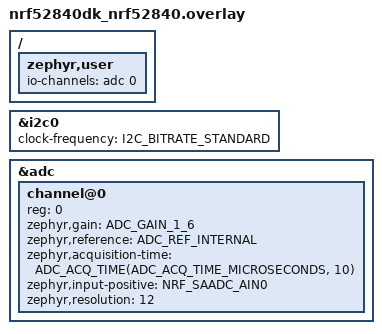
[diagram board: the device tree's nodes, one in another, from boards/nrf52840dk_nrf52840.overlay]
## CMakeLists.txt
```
#
# CMakeLists.txt -- IAQ edge node (nRF52840 DK)
#
cmake_minimum_required(VERSION 3.20.0)

find_package(Zephyr REQUIRED HINTS $ENV{ZEPHYR_BASE})
project(iaq_edge_node)

target_sources(app PRIVATE
    src/main.c
    src/sensirion_common.c
    src/scd41.c
    src/sps30.c
    src/ccs811.c
    src/mcp9808.c
    src/ldr.c
)
```

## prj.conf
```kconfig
# prj.conf -- IAQ edge node

# ---- Bluetooth: broadcaster / beacon only ----
CONFIG_BT=y
CONFIG_BT_PERIPHERAL=n
CONFIG_BT_CENTRAL=n
CONFIG_BT_BROADCASTER=y
CONFIG_BT_DEVICE_NAME="IAQ-Node"

# ---- Peripherals ----
CONFIG_I2C=y
CONFIG_ADC=y

# ---- Sensor maths needs float printf ----
CONFIG_FPU=y
CONFIG_CBPRINTF_FP_SUPPORT=y
CONFIG_NEWLIB_LIBC=y
CONFIG_NEWLIB_LIBC_FLOAT_PRINTF=y

# ---- Logging over RTT (works without a UART cable) ----
CONFIG_LOG=y
CONFIG_USE_SEGGER_RTT=y
CONFIG_LOG_BACKEND_RTT=y
CONFIG_LOG_BACKEND_UART=n

# Roomier main stack for the sensor work
CONFIG_MAIN_STACK_SIZE=4096
```

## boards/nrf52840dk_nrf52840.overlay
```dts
/*
 * nrf52840dk_nrf52840.overlay -- IAQ edge node
 *
 * I2C0 on the nRF52840 DK Arduino header defaults to:
 *     SDA = P0.26 , SCL = P0.27
 * All I2C sensors (SCD41, SPS30, CCS811, MCP9808) share this bus.
 * If you want different pins, add a &pinctrl block; otherwise these are used.
 *
 * The LDR divider midpoint goes to analog input AIN0 = P0.02.
 */

&i2c0 {
	status = "okay";
	clock-frequency = <I2C_BITRATE_STANDARD>;   /* 100 kHz -- safest */
};

/* SAADC channel 0 -> AIN0 (P0.02) for the LDR divider. */
&adc {
	status = "okay";
	#address-cells = <1>;
	#size-cells = <0>;

	channel@0 {
		reg = <0>;
		zephyr,gain = "ADC_GAIN_1_6";
		zephyr,reference = "ADC_REF_INTERNAL";
		zephyr,acquisition-time = <ADC_ACQ_TIME(ADC_ACQ_TIME_MICROSECONDS, 10)>;
		zephyr,input-positive = <NRF_SAADC_AIN0>;
		zephyr,resolution = <12>;
	};
};

/ {
	zephyr,user {
		io-channels = <&adc 0>;
	};
};
```

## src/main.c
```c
/*
 * main.c -- Edge node (nRF52840 DK) for the Indoor Air-Pollution Monitor.
 *
 * Flow:
 *   1. Bring up Bluetooth and start non-connectable advertising (beacon).
 *   2. Initialise every sensor (a failing sensor is non-fatal -- its field
 *      simply stays 0, so you can bring the system up one sensor at a time).
 *   3. Every SAMPLE_INTERVAL_S: read sensors, EMA-filter the slow gases,
 *      run the derivative spike check (proposal eq. 2/3), bit-pack the
 *      18-byte payload, refresh the advertisement, and print a JSON line
 *      over the console (RTT / UART) for local debugging.
 *
 * BRING-UP TIP: start with only ENABLE_SCD41 defined to 1 and the rest 0.
 * Get CO2 printing + advertising first, THEN switch the others on one by one.
 */
#include <zephyr/kernel.h>
#include <zephyr/logging/log.h>
#include <zephyr/bluetooth/bluetooth.h>
#include <string.h>

#include "payload.h"
#include "ema.h"
#include "scd41.h"
#include "sps30.h"
#include "ccs811.h"
#include "mcp9808.h"
#include "ldr.h"

LOG_MODULE_REGISTER(main, LOG_LEVEL_INF);

/* ---- Feature switches (set to 0 to disable a sensor during bring-up) ---- */
#define ENABLE_SCD41   1
#define ENABLE_MCP9808 1
#define ENABLE_SPS30   1
#define ENABLE_CCS811  1
#define ENABLE_LDR     1

/* ---- Tunables ---- */
#define SAMPLE_INTERVAL_S 5     /* proposal target is 60 s for power saving */
#define ALPHA_CO2  0.15f        /* proposal: slow gases */
#define ALPHA_PM   0.40f        /* proposal: particulate */
#define GAMMA_CO2  10.0f        /* ppm/s spike threshold (eq. 3) */

/* ---- Advertising data ---- */
static uint8_t mfg[IAQ_PAYLOAD_LEN];

static struct bt_data ad[] = {
	BT_DATA_BYTES(BT_DATA_FLAGS, BT_LE_AD_NO_BREDR),
	BT_DATA(BT_DATA_MANUFACTURER_DATA, mfg, sizeof(mfg)),
};

static void put_le16(uint8_t *p, uint16_t v)
{
	p[0] = (uint8_t)(v & 0xFF);
	p[1] = (uint8_t)(v >> 8);
}

int main(void)
{
	int rc;
	uint8_t seq = 0;

	ema_t ema_co2, ema_pm, ema_tvoc;
	ema_init(&ema_co2, ALPHA_CO2);
	ema_init(&ema_pm, ALPHA_PM);
	ema_init(&ema_tvoc, ALPHA_CO2);
	float prev_co2 = 0.0f;
	bool have_prev = false;

	LOG_INF("=== IAQ edge node starting ===");

	/* Company ID is constant -- write it once. */
	put_le16(&mfg[0], IAQ_COMPANY_ID);

	rc = bt_enable(NULL);
	if (rc) {
		LOG_ERR("bt_enable failed (%d)", rc);
		return 0;
	}
	rc = bt_le_adv_start(BT_LE_ADV_NCONN, ad, ARRAY_SIZE(ad), NULL, 0);
	if (rc) {
		LOG_ERR("adv start failed (%d)", rc);
		return 0;
	}
	LOG_INF("Advertising as non-connectable beacon");

#if ENABLE_SCD41
	if (scd41_init())   LOG_WRN("SCD41 init failed");
#endif
#if ENABLE_MCP9808
	if (mcp9808_init()) LOG_WRN("MCP9808 init failed");
#endif
#if ENABLE_SPS30
	if (sps30_init())   LOG_WRN("SPS30 init failed");
#endif
#if ENABLE_CCS811
	if (ccs811_init())  LOG_WRN("CCS811 init failed");
#endif
#if ENABLE_LDR
	if (ldr_init())     LOG_WRN("LDR init failed");
#endif

	while (1) {
		k_sleep(K_SECONDS(SAMPLE_INTERVAL_S));

		uint16_t co2 = 0, rh_centi = 0, pm25_deci = 0;
		uint16_t tvoc = 0, eco2 = 0, lux = 0;
		int16_t  temp_centi = 0;

#if ENABLE_SCD41
		scd41_sample_t s;
		if (scd41_data_ready() && scd41_read(&s) == 0 && s.valid) {
			float f = ema_update(&ema_co2, (float)s.co2_ppm);
			co2 = (uint16_t)f;
			rh_centi = (uint16_t)(s.rh_percent * 100.0f);

			/* Spike detection: dy/Ts > gamma  (eqs. 2 & 3). */
			if (have_prev) {
				float dy = (f - prev_co2) / (float)SAMPLE_INTERVAL_S;
				if (dy > GAMMA_CO2) {
					LOG_WRN("CO2 SPIKE  dy=%.1f ppm/s", (double)dy);
				}
			}
			prev_co2 = f;
			have_prev = true;
		}
#endif
#if ENABLE_MCP9808
		mcp9808_sample_t t;
		if (mcp9808_read(&t) == 0 && t.valid) {
			temp_centi = (int16_t)(t.temp_c * 100.0f);
		}
#endif
#if ENABLE_SPS30
		sps30_sample_t p;
		if (sps30_data_ready() && sps30_read(&p) == 0 && p.valid) {
			float f = ema_update(&ema_pm, p.pm2_5);
			pm25_deci = (uint16_t)(f * 10.0f);
		}
#endif
#if ENABLE_CCS811
		ccs811_sample_t c;
		if (ccs811_data_ready() && ccs811_read(&c) == 0 && c.valid) {
			tvoc = (uint16_t)ema_update(&ema_tvoc, (float)c.tvoc_ppb);
			eco2 = c.eco2_ppm;
		}
#endif
#if ENABLE_LDR
		ldr_sample_t l;
		if (ldr_read(&l) == 0 && l.valid) {
			lux = l.lux;
		}
#endif

		/* ---- Pack payload (offsets per payload.h) ---- */
		put_le16(&mfg[2],  co2);
		put_le16(&mfg[4],  (uint16_t)temp_centi);
		put_le16(&mfg[6],  rh_centi);
		put_le16(&mfg[8],  pm25_deci);
		put_le16(&mfg[10], tvoc);
		put_le16(&mfg[12], eco2);
		put_le16(&mfg[14], lux);
		mfg[16] = seq++;
		mfg[17] = iaq_crc8(&mfg[2], 15);

		rc = bt_le_adv_update_data(ad, ARRAY_SIZE(ad), NULL, 0);
		if (rc) {
			LOG_WRN("adv update failed (%d)", rc);
		}

		/* Local debug line (mirrors the gateway JSON). */
		LOG_INF("{\"co2\":%u,\"temp\":%d.%02d,\"rh\":%u.%02u,"
			"\"pm25\":%u.%u,\"tvoc\":%u,\"eco2\":%u,\"lux\":%u,\"pkt\":%u}",
			co2, temp_centi / 100, (temp_centi % 100 + 100) % 100,
			rh_centi / 100, rh_centi % 100,
			pm25_deci / 10, pm25_deci % 10, tvoc, eco2, lux, mfg[16]);
	}
	return 0;
}
```

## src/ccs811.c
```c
/*
 * ccs811.c -- AMS CCS811 driver (raw I2C).
 *
 * Register map:
 *   0x00 STATUS        (bit7 FW_MODE, bit4 APP_VALID, bit3 DATA_READY)
 *   0x01 MEAS_MODE     write drive mode
 *   0x02 ALG_RESULT_DATA  (eCO2 hi/lo, TVOC hi/lo, status, error, ...)
 *   0x20 HW_ID         should read 0x81
 *   0xF4 APP_START     (no data) -- switch from boot to application mode
 *
 * Notes:
 *  - First valid readings appear after ~20 min of run-in conditioning.
 *    Until then the numbers are coarse; that is normal for this part.
 */
#include "ccs811.h"
#include <zephyr/kernel.h>
#include <zephyr/drivers/i2c.h>
#include <zephyr/logging/log.h>

LOG_MODULE_REGISTER(ccs811, LOG_LEVEL_INF);

#define CCS811_ADDR 0x5A

#define REG_STATUS      0x00
#define REG_MEAS_MODE   0x01
#define REG_ALG_RESULT  0x02
#define REG_HW_ID       0x20
#define REG_APP_START   0xF4

#define DRIVE_MODE_1SEC 0x10 /* MEAS_MODE: measurement every 1 s, INT off */

static const struct i2c_dt_spec ccs811 = {
	.bus  = DEVICE_DT_GET(DT_NODELABEL(i2c0)),
	.addr = CCS811_ADDR,
};

static int read_reg(uint8_t reg, uint8_t *buf, uint8_t len)
{
	return i2c_write_read_dt(&ccs811, &reg, 1, buf, len);
}

int ccs811_init(void)
{
	if (!device_is_ready(ccs811.bus)) {
		return -ENODEV;
	}

	uint8_t hw_id = 0;
	int rc = read_reg(REG_HW_ID, &hw_id, 1);
	if (rc || hw_id != 0x81) {
		LOG_ERR("HW_ID = 0x%02x (expected 0x81), rc=%d", hw_id, rc);
		return -ENODEV;
	}

	/* Switch from boot mode to application mode (APP_START, no payload). */
	uint8_t app_start = REG_APP_START;
	rc = i2c_write_dt(&ccs811, &app_start, 1);
	if (rc) {
		return rc;
	}
	k_msleep(20);

	/* Configure continuous 1 s measurement mode. */
	uint8_t meas[2] = { REG_MEAS_MODE, DRIVE_MODE_1SEC };
	rc = i2c_write_dt(&ccs811, meas, sizeof(meas));
	if (rc) {
		return rc;
	}
	LOG_INF("CCS811 in app mode (allow ~20 min run-in for accuracy)");
	return 0;
}

bool ccs811_data_ready(void)
{
	uint8_t status = 0;
	if (read_reg(REG_STATUS, &status, 1)) {
		return false;
	}
	return (status & 0x08) != 0; /* DATA_READY */
}

int ccs811_read(ccs811_sample_t *out)
{
	uint8_t d[4];
	out->valid = false;

	int rc = read_reg(REG_ALG_RESULT, d, sizeof(d));
	if (rc) {
		return rc;
	}
	out->eco2_ppm = (uint16_t)((d[0] << 8) | d[1]);
	out->tvoc_ppb = (uint16_t)((d[2] << 8) | d[3]);
	out->valid    = true;
	return 0;
}
```

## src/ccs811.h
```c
/*
 * ccs811.h -- AMS CCS811 air-quality sensor (TVOC + eCO2).
 * Default I2C address 0x5A (ADDR pin low). WAKE pin MUST be tied to GND
 * (or driven low) for I2C to respond.
 */
#ifndef CCS811_H
#define CCS811_H

#include <stdint.h>
#include <stdbool.h>

typedef struct {
	uint16_t eco2_ppm;  /* equivalent CO2, 400..8192 ppm  */
	uint16_t tvoc_ppb;  /* total VOC, 0..1187 ppb         */
	bool     valid;
} ccs811_sample_t;

int  ccs811_init(void);
bool ccs811_data_ready(void);
int  ccs811_read(ccs811_sample_t *out);

#endif /* CCS811_H */
```

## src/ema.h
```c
/*
 * ema.h -- Exponential Moving Average low-pass filter.
 * Implements proposal eq. (1):  y[n] = a*x[n] + (1-a)*y[n-1]
 */
#ifndef EMA_H
#define EMA_H

#include <stdbool.h>

typedef struct {
	float alpha;
	float y;
	bool  initialised;
} ema_t;

static inline void ema_init(ema_t *f, float alpha)
{
	f->alpha = alpha;
	f->y = 0.0f;
	f->initialised = false;
}

static inline float ema_update(ema_t *f, float x)
{
	if (!f->initialised) {
		f->y = x;            /* seed with first sample */
		f->initialised = true;
	} else {
		f->y = f->alpha * x + (1.0f - f->alpha) * f->y;
	}
	return f->y;
}

#endif /* EMA_H */
```

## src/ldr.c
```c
/*
 * ldr.c -- LDR read via Zephyr ADC (SAADC) using a devicetree io-channel.
 *
 * The overlay defines:
 *   zephyr,user { io-channels = <&adc 0>; };
 *   &adc { channel@0 { reg=<0>; zephyr,gain="ADC_GAIN_1_6";
 *          zephyr,reference="ADC_REF_INTERNAL"; zephyr,acquisition-time=...;
 *          zephyr,input-positive=<NRF_SAADC_AIN0>; }; };
 *
 * Lux estimate (rough): with the LDR on the top of the divider and Rfixed
 * to GND, brighter light -> lower R_LDR -> higher midpoint voltage.
 * Calibrate LDR_K / LDR_BETA against a reference meter for real lux.
 */
#include "ldr.h"
#include <zephyr/kernel.h>
#include <zephyr/drivers/adc.h>
#include <zephyr/logging/log.h>
#include <math.h>

LOG_MODULE_REGISTER(ldr, LOG_LEVEL_INF);

#define VDD_MV       3300.0f
#define R_FIXED_OHMS 10000.0f   /* divider resistor to GND */
#define LDR_K        500000.0f  /* empirical -- CALIBRATE */
#define LDR_BETA     1.4f       /* empirical -- CALIBRATE */

static const struct adc_dt_spec adc_ch =
	ADC_DT_SPEC_GET(DT_PATH(zephyr_user));

static int16_t sample_buf;
static struct adc_sequence seq = {
	.buffer      = &sample_buf,
	.buffer_size = sizeof(sample_buf),
};

int ldr_init(void)
{
	if (!adc_is_ready_dt(&adc_ch)) {
		LOG_ERR("ADC not ready");
		return -ENODEV;
	}
	int rc = adc_channel_setup_dt(&adc_ch);
	if (rc) {
		LOG_ERR("adc_channel_setup failed (%d)", rc);
		return rc;
	}
	(void)adc_sequence_init_dt(&adc_ch, &seq);
	return 0;
}

int ldr_read(ldr_sample_t *out)
{
	out->valid = false;

	int rc = adc_read_dt(&adc_ch, &seq);
	if (rc) {
		return rc;
	}

	int32_t mv = sample_buf;
	rc = adc_raw_to_millivolts_dt(&adc_ch, &mv);
	if (rc) {
		return rc;
	}
	if (mv < 1) {
		mv = 1;
	}
	out->millivolts = (uint16_t)mv;

	/* R_LDR from the divider, then lux = K * R_LDR^-beta. */
	float v = (float)mv;
	float r_ldr = R_FIXED_OHMS * (VDD_MV / v - 1.0f);
	if (r_ldr < 1.0f) {
		r_ldr = 1.0f;
	}
	float lux = LDR_K * powf(r_ldr, -LDR_BETA);
	if (lux > 65535.0f) {
		lux = 65535.0f;
	}
	out->lux   = (uint16_t)lux;
	out->valid = true;
	return 0;
}
```

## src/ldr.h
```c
/*
 * ldr.h -- Iduino LDR light sensor read via nRF52840 SAADC.
 * The LDR forms a divider with a fixed pull-up; the divider midpoint is wired
 * to analog input AIN0 (P0.02 on the nRF52840 DK). See the board overlay.
 */
#ifndef LDR_H
#define LDR_H

#include <stdint.h>
#include <stdbool.h>

typedef struct {
	uint16_t millivolts; /* measured divider voltage */
	uint16_t lux;        /* estimated illuminance (calibrate constants) */
	bool     valid;
} ldr_sample_t;

int ldr_init(void);
int ldr_read(ldr_sample_t *out);

#endif /* LDR_H */
```

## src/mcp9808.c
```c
/*
 * mcp9808.c -- Microchip MCP9808 driver (raw I2C).
 *
 * Ambient temperature register 0x05 returns 2 bytes:
 *   bits 12..0 = temperature in 1/16 degC, bit 12 = sign.
 */
#include "mcp9808.h"
#include <zephyr/drivers/i2c.h>
#include <zephyr/logging/log.h>

LOG_MODULE_REGISTER(mcp9808, LOG_LEVEL_INF);

#define MCP9808_ADDR     0x18
#define REG_AMBIENT_TEMP 0x05

static const struct i2c_dt_spec mcp = {
	.bus  = DEVICE_DT_GET(DT_NODELABEL(i2c0)),
	.addr = MCP9808_ADDR,
};

int mcp9808_init(void)
{
	if (!device_is_ready(mcp.bus)) {
		return -ENODEV;
	}
	return 0;
}

int mcp9808_read(mcp9808_sample_t *out)
{
	uint8_t reg = REG_AMBIENT_TEMP;
	uint8_t d[2];
	out->valid = false;

	int rc = i2c_write_read_dt(&mcp, &reg, 1, d, sizeof(d));
	if (rc) {
		return rc;
	}

	uint16_t raw = (uint16_t)((d[0] << 8) | d[1]);
	raw &= 0x1FFF;          /* keep 13 data bits */
	float t = (float)raw / 16.0f;
	if (d[0] & 0x10) {      /* sign bit */
		t -= 256.0f;
	}
	out->temp_c = t;
	out->valid  = true;
	return 0;
}
```

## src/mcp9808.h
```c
/*
 * mcp9808.h -- Microchip MCP9808 high-accuracy temperature sensor.
 * Default I2C address 0x18 (A0..A2 low).
 */
#ifndef MCP9808_H
#define MCP9808_H

#include <stdbool.h>

typedef struct {
	float temp_c;
	bool  valid;
} mcp9808_sample_t;

int mcp9808_init(void);
int mcp9808_read(mcp9808_sample_t *out);

#endif /* MCP9808_H */
```

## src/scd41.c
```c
/*
 * scd41.c -- Sensirion SCD41 driver (raw I2C).
 *
 * Command reference (from SCD4x datasheet):
 *   0x21B1  start_periodic_measurement   (new sample every 5 s)
 *   0xE4B8  get_data_ready_status
 *   0xEC05  read_measurement             (CO2, T, RH, each word + CRC)
 *   0x3F86  stop_periodic_measurement
 *   0x3646  reinit
 *
 * Conversion (datasheet):
 *   CO2 [ppm] = word0
 *   T  [degC] = -45 + 175 * word1 / 65535
 *   RH [%]    =       100 * word2 / 65535
 */
#include "scd41.h"
#include "sensirion_common.h"
#include <zephyr/kernel.h>
#include <zephyr/logging/log.h>

LOG_MODULE_REGISTER(scd41, LOG_LEVEL_INF);

#define SCD41_ADDR 0x62

/* i2c0 is the I2C controller enabled in the board overlay. */
static const struct i2c_dt_spec scd41 = {
	.bus  = DEVICE_DT_GET(DT_NODELABEL(i2c0)),
	.addr = SCD41_ADDR,
};

int scd41_init(void)
{
	if (!device_is_ready(scd41.bus)) {
		LOG_ERR("I2C bus not ready");
		return -ENODEV;
	}

	/* Make sure we are not already measuring, then (re)start. */
	(void)sensirion_write_cmd(&scd41, 0x3F86); /* stop_periodic_measurement */
	k_msleep(500);
	(void)sensirion_write_cmd(&scd41, 0x3646); /* reinit */
	k_msleep(30);

	int rc = sensirion_write_cmd(&scd41, 0x21B1); /* start_periodic_measurement */
	if (rc) {
		LOG_ERR("start_periodic_measurement failed (%d)", rc);
		return rc;
	}
	LOG_INF("SCD41 measuring (first sample ~5 s)");
	return 0;
}

bool scd41_data_ready(void)
{
	uint16_t status;
	int rc = sensirion_read_words(&scd41, 0xE4B8, 1, &status, 1);
	if (rc) {
		return false;
	}
	/* Bits 0..10 == 0 means "not ready". */
	return (status & 0x07FF) != 0;
}

int scd41_read(scd41_sample_t *out)
{
	uint16_t w[3];
	int rc = sensirion_read_words(&scd41, 0xEC05, 1, w, 3);
	if (rc) {
		out->valid = false;
		return rc;
	}
	out->co2_ppm    = w[0];
	out->temp_c     = -45.0f + 175.0f * (float)w[1] / 65535.0f;
	out->rh_percent =          100.0f * (float)w[2] / 65535.0f;
	out->valid      = true;
	return 0;
}
```

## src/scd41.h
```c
/*
 * scd41.h -- Sensirion SCD41 CO2 / temperature / humidity sensor.
 * I2C address 0x62. Raw-I2C driver (no devicetree binding required).
 */
#ifndef SCD41_H
#define SCD41_H

#include <stdint.h>
#include <stdbool.h>

typedef struct {
	uint16_t co2_ppm;    /* parts per million */
	float    temp_c;     /* degrees Celsius   */
	float    rh_percent; /* %RH               */
	bool     valid;
} scd41_sample_t;

/* Initialise the bus spec and start periodic measurement. */
int scd41_init(void);

/* True once at least 5 s have passed and new data is ready. */
bool scd41_data_ready(void);

/* Read one sample. Call only after scd41_data_ready() returns true. */
int scd41_read(scd41_sample_t *out);

#endif /* SCD41_H */
```

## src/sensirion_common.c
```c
/*
 * sensirion_common.c  -- see header for description.
 */
#include "sensirion_common.h"
#include <zephyr/kernel.h>

uint8_t sensirion_crc8(const uint8_t *data, uint16_t count)
{
	uint8_t crc = 0xFF;
	for (uint16_t i = 0; i < count; i++) {
		crc ^= data[i];
		for (uint8_t bit = 0; bit < 8; bit++) {
			if (crc & 0x80) {
				crc = (uint8_t)((crc << 1) ^ 0x31);
			} else {
				crc = (uint8_t)(crc << 1);
			}
		}
	}
	return crc;
}

int sensirion_write_cmd(const struct i2c_dt_spec *dev, uint16_t cmd)
{
	uint8_t buf[2] = { (uint8_t)(cmd >> 8), (uint8_t)(cmd & 0xFF) };
	return i2c_write_dt(dev, buf, sizeof(buf));
}

int sensirion_write_cmd_arg(const struct i2c_dt_spec *dev, uint16_t cmd,
			    uint16_t arg)
{
	uint8_t buf[5];
	buf[0] = (uint8_t)(cmd >> 8);
	buf[1] = (uint8_t)(cmd & 0xFF);
	buf[2] = (uint8_t)(arg >> 8);
	buf[3] = (uint8_t)(arg & 0xFF);
	buf[4] = sensirion_crc8(&buf[2], 2);
	return i2c_write_dt(dev, buf, sizeof(buf));
}

int sensirion_read_words(const struct i2c_dt_spec *dev, uint16_t cmd,
			 uint32_t delay_ms, uint16_t *out, uint8_t num_words)
{
	int rc;
	uint8_t cmd_buf[2] = { (uint8_t)(cmd >> 8), (uint8_t)(cmd & 0xFF) };

	rc = i2c_write_dt(dev, cmd_buf, sizeof(cmd_buf));
	if (rc) {
		return rc;
	}

	if (delay_ms) {
		k_msleep(delay_ms);
	}

	/* Each word on the wire is 3 bytes: MSB, LSB, CRC. */
	uint8_t rx[3 * 32];
	if (num_words > 32) {
		return -EINVAL;
	}
	rc = i2c_read_dt(dev, rx, (size_t)num_words * 3);
	if (rc) {
		return rc;
	}

	for (uint8_t i = 0; i < num_words; i++) {
		uint8_t *w = &rx[i * 3];
		if (sensirion_crc8(w, 2) != w[2]) {
			return -EIO; /* CRC mismatch */
		}
		out[i] = (uint16_t)((w[0] << 8) | w[1]);
	}
	return 0;
}
```

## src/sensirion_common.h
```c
/*
 * sensirion_common.h
 * Shared helpers for Sensirion-family I2C sensors (SCD41, SPS30).
 *
 * Sensirion sensors append a CRC-8 to every 2-byte word on the I2C bus.
 *   polynomial = 0x31, init = 0xFF, no reflection, final XOR = 0x00.
 *
 * These helpers are written against the Zephyr <zephyr/drivers/i2c.h> API
 * so they work on any nRF Connect SDK / Zephyr version.
 */
#ifndef SENSIRION_COMMON_H
#define SENSIRION_COMMON_H

#include <stdint.h>
#include <stdbool.h>
#include <zephyr/drivers/i2c.h>

/* Compute Sensirion CRC-8 over `count` bytes. */
uint8_t sensirion_crc8(const uint8_t *data, uint16_t count);

/*
 * Send a 16-bit command to the sensor (MSB first).
 * Returns 0 on success, negative errno on failure.
 */
int sensirion_write_cmd(const struct i2c_dt_spec *dev, uint16_t cmd);

/*
 * Send a 16-bit command followed by one 16-bit argument plus its CRC.
 */
int sensirion_write_cmd_arg(const struct i2c_dt_spec *dev, uint16_t cmd,
			    uint16_t arg);

/*
 * Send a 16-bit command, wait `delay_ms`, then read `num_words` 16-bit words.
 * Each word is validated against its CRC byte. Decoded words are written to
 * `out` (host byte order). Returns 0 on success, -EIO on CRC mismatch.
 */
int sensirion_read_words(const struct i2c_dt_spec *dev, uint16_t cmd,
			 uint32_t delay_ms, uint16_t *out, uint8_t num_words);

#endif /* SENSIRION_COMMON_H */
```

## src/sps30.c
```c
/*
 * sps30.c -- Sensirion SPS30 driver (raw I2C, IEEE-754 float output mode).
 *
 * Command reference (SPS30 I2C datasheet):
 *   0x0010 start_measurement   arg 0x0300 => big-endian float output
 *   0x0104 stop_measurement
 *   0x0202 read_data_ready_flag        (1 word)
 *   0x0300 read_measured_values        (10 floats, 60 bytes, float mode)
 *   0xD033 device_reset
 *
 * In float mode a value occupies 6 bytes on the wire:
 *   [word_hi_MSB][word_hi_LSB][CRC][word_lo_MSB][word_lo_LSB][CRC]
 * The float (big-endian IEEE754) is bytes: hi_MSB hi_LSB lo_MSB lo_LSB.
 * The first four values are PM1.0, PM2.5, PM4.0, PM10 mass conc. (ug/m3).
 */
#include "sps30.h"
#include "sensirion_common.h"
#include <string.h>
#include <zephyr/kernel.h>
#include <zephyr/logging/log.h>

LOG_MODULE_REGISTER(sps30, LOG_LEVEL_INF);

#define SPS30_ADDR 0x69

static const struct i2c_dt_spec sps30 = {
	.bus  = DEVICE_DT_GET(DT_NODELABEL(i2c0)),
	.addr = SPS30_ADDR,
};

int sps30_init(void)
{
	if (!device_is_ready(sps30.bus)) {
		return -ENODEV;
	}

	(void)sensirion_write_cmd(&sps30, 0xD033); /* reset */
	k_msleep(100);

	/* start_measurement, float output (0x03), dummy 0x00 */
	int rc = sensirion_write_cmd_arg(&sps30, 0x0010, 0x0300);
	if (rc) {
		LOG_ERR("start_measurement failed (%d)", rc);
		return rc;
	}
	/* Fan spin-up: data becomes stable after a few seconds. */
	k_msleep(1000);
	LOG_INF("SPS30 measuring");
	return 0;
}

bool sps30_data_ready(void)
{
	uint16_t flag;
	int rc = sensirion_read_words(&sps30, 0x0202, 5, &flag, 1);
	if (rc) {
		return false;
	}
	return (flag & 0x0001) != 0;
}

static float be_bytes_to_float(const uint8_t b[4])
{
	uint32_t u = ((uint32_t)b[0] << 24) | ((uint32_t)b[1] << 16) |
		     ((uint32_t)b[2] << 8) | (uint32_t)b[3];
	float f;
	memcpy(&f, &u, sizeof(f));
	return f;
}

int sps30_read(sps30_sample_t *out)
{
	uint8_t cmd[2] = { 0x03, 0x00 };
	uint8_t rx[60];

	out->valid = false;

	int rc = i2c_write_dt(&sps30, cmd, sizeof(cmd));
	if (rc) {
		return rc;
	}
	k_msleep(5);
	rc = i2c_read_dt(&sps30, rx, sizeof(rx));
	if (rc) {
		return rc;
	}

	/* Verify CRC on every 2-byte word (20 words total). */
	for (int i = 0; i < 60; i += 3) {
		if (sensirion_crc8(&rx[i], 2) != rx[i + 2]) {
			LOG_WRN("SPS30 CRC error at byte %d", i);
			return -EIO;
		}
	}

	/* Reconstruct float i from 6-byte block starting at 6*i. */
	float vals[4];
	for (int i = 0; i < 4; i++) {
		const uint8_t *p = &rx[i * 6];
		uint8_t fb[4] = { p[0], p[1], p[3], p[4] };
		vals[i] = be_bytes_to_float(fb);
	}
	out->pm1_0 = vals[0];
	out->pm2_5 = vals[1];
	out->pm4_0 = vals[2];
	out->pm10  = vals[3];
	out->valid = true;
	return 0;
}
```
